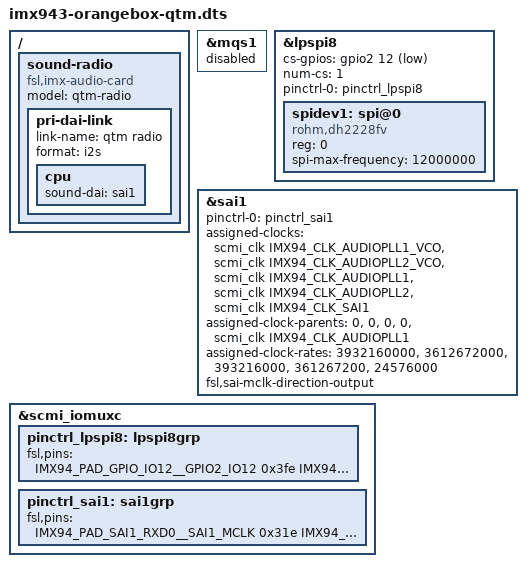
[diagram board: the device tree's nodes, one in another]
// SPDX-License-Identifier: (GPL-2.0+ OR MIT)
/*
 * Copyright 2024-2025 NXP
 */

/dts-v1/;

#include "imx943-orangebox.dts"

/ {
	sound-radio {
		compatible = "fsl,imx-audio-card";
		model = "qtm-radio";
		pri-dai-link {
			link-name = "qtm radio";
			format = "i2s";
			cpu {
				sound-dai = <&sai1>;
			};
		};
	};
};

&mqs1 {
	status = "disabled";
};

&lpspi8 {
	cs-gpios = <&gpio2 12 GPIO_ACTIVE_LOW>;
	num-cs = <1>;
	pinctrl-0 = <&pinctrl_lpspi8>;
	pinctrl-names = "default";
	status = "okay";

	spidev1: spi@0 {
		compatible = "rohm,dh2228fv";
		reg = <0>;
		spi-max-frequency = <12000000>;
	};
};

&sai1 {
	#sound-dai-cells = <0>;
	pinctrl-names = "default";
	pinctrl-0 = <&pinctrl_sai1>;
	assigned-clocks = <&scmi_clk IMX94_CLK_AUDIOPLL1_VCO>,
			<&scmi_clk IMX94_CLK_AUDIOPLL2_VCO>,
			<&scmi_clk IMX94_CLK_AUDIOPLL1>,
			<&scmi_clk IMX94_CLK_AUDIOPLL2>,
			<&scmi_clk IMX94_CLK_SAI1>;
	assigned-clock-parents = <0>, <0>, <0>, <0>,
			<&scmi_clk IMX94_CLK_AUDIOPLL1>;
	assigned-clock-rates = <3932160000>,
			<3612672000>, <393216000>,
			<361267200>, <24576000>;
	fsl,sai-mclk-direction-output;
	status = "okay";
};

&scmi_iomuxc {
	pinctrl_lpspi8: lpspi8grp {
		fsl,pins = <
			IMX94_PAD_GPIO_IO12__GPIO2_IO12			0x3fe
			IMX94_PAD_GPIO_IO13__LPSPI8_SIN			0x3fe
			IMX94_PAD_GPIO_IO14__LPSPI8_SOUT		0x3fe
			IMX94_PAD_GPIO_IO15__LPSPI8_SCK			0x3fe
		>;
	};

	pinctrl_sai1: sai1grp {
		fsl,pins = <
			IMX94_PAD_SAI1_RXD0__SAI1_MCLK				0x31e
			IMX94_PAD_SAI1_TXC__SAI1_TX_BCLK			0x31e
			IMX94_PAD_SAI1_TXFS__SAI1_TX_SYNC			0x31e
			IMX94_PAD_SAI1_RXD0__SAI1_RX_DATA0			0x31e
			IMX94_PAD_SAI1_TXD0__SAI1_TX_DATA0 			0x31e
		>;
	};

};
